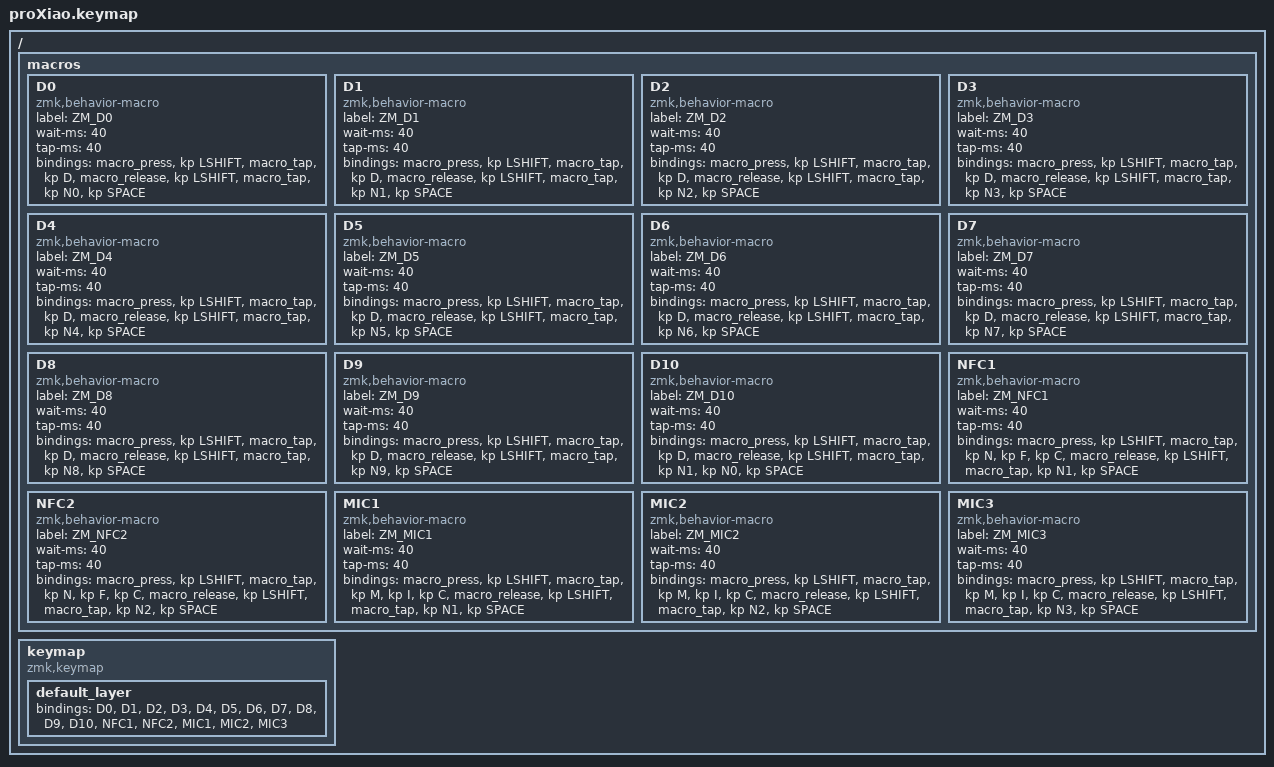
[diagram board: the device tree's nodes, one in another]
/*
 * Copyright (c) 2020 The ZMK Contributors
 *
 * SPDX-License-Identifier: MIT
 */

#include <behaviors.dtsi>
#include <dt-bindings/zmk/keys.h>
#include <dt-bindings/zmk/bt.h>

#include <dt-bindings/zmk/ext_power.h>


/ {
    macros {
        D0: D0 {
            label = "ZM_D0";
            compatible = "zmk,behavior-macro";
            #binding-cells = <0>;
            wait-ms = <40>;
            tap-ms = <40>;
            bindings
                = <&macro_press   &kp LSHIFT>    
                , <&macro_tap     &kp D>
                , <&macro_release &kp LSHIFT>
                , <&macro_tap     &kp N0  &kp SPACE> 
                ;
        };
        D1: D1 {
            label = "ZM_D1";
            compatible = "zmk,behavior-macro";
            #binding-cells = <0>;
            wait-ms = <40>;
            tap-ms = <40>;
            bindings
                = <&macro_press   &kp LSHIFT>    
                , <&macro_tap     &kp D> 
                , <&macro_release &kp LSHIFT>
                , <&macro_tap     &kp N1  &kp SPACE> 
                ;
        };
        D2: D2 {
            label = "ZM_D2";
            compatible = "zmk,behavior-macro";
            #binding-cells = <0>;
            wait-ms = <40>;
            tap-ms = <40>;
            bindings
                = <&macro_press   &kp LSHIFT>    
                , <&macro_tap     &kp D>   
                , <&macro_release &kp LSHIFT>
                , <&macro_tap     &kp N2  &kp SPACE> 
                ;
        };
        D3: D3 {
            label = "ZM_D3";
            compatible = "zmk,behavior-macro";
            #binding-cells = <0>;
            wait-ms = <40>;
            tap-ms = <40>;
            bindings
                = <&macro_press   &kp LSHIFT>    
                , <&macro_tap     &kp D>   
                , <&macro_release &kp LSHIFT>
                , <&macro_tap     &kp N3  &kp SPACE> 
                ;
        };
        D4: D4 {
            label = "ZM_D4";
            compatible = "zmk,behavior-macro";
            #binding-cells = <0>;
            wait-ms = <40>;
            tap-ms = <40>;
            bindings
                = <&macro_press   &kp LSHIFT>    
                , <&macro_tap     &kp D>   
                , <&macro_release &kp LSHIFT>
                , <&macro_tap     &kp N4  &kp SPACE> 
                ;
        };
        D5: D5 {
            label = "ZM_D5";
            compatible = "zmk,behavior-macro";
            #binding-cells = <0>;
            wait-ms = <40>;
            tap-ms = <40>;
            bindings
                = <&macro_press   &kp LSHIFT>    
                , <&macro_tap     &kp D>   
                , <&macro_release &kp LSHIFT>
                , <&macro_tap     &kp N5  &kp SPACE> 
                ;
        };
        D6: D6 {
            label = "ZM_D6";
            compatible = "zmk,behavior-macro";
            #binding-cells = <0>;
            wait-ms = <40>;
            tap-ms = <40>;
            bindings
                = <&macro_press   &kp LSHIFT>    
                , <&macro_tap     &kp D>   
                , <&macro_release &kp LSHIFT>
                , <&macro_tap     &kp N6  &kp SPACE> 
                ;
        };
        D7: D7 {
            label = "ZM_D7";
            compatible = "zmk,behavior-macro";
            #binding-cells = <0>;
            wait-ms = <40>;
            tap-ms = <40>;
            bindings
                = <&macro_press   &kp LSHIFT>    
                , <&macro_tap     &kp D>   
                , <&macro_release &kp LSHIFT>
                , <&macro_tap     &kp N7  &kp SPACE> 
                ;
        };
        D8: D8 {
            label = "ZM_D8";
            compatible = "zmk,behavior-macro";
            #binding-cells = <0>;
            wait-ms = <40>;
            tap-ms = <40>;
            bindings
                = <&macro_press   &kp LSHIFT>    
                , <&macro_tap     &kp D>   
                , <&macro_release &kp LSHIFT>
                , <&macro_tap     &kp N8  &kp SPACE>  
                ;
        };
        D9: D9 {
            label = "ZM_D9";
            compatible = "zmk,behavior-macro";
            #binding-cells = <0>;
            wait-ms = <40>;
            tap-ms = <40>;
            bindings
                = <&macro_press   &kp LSHIFT>    
                , <&macro_tap     &kp D>
                , <&macro_release &kp LSHIFT>
                , <&macro_tap     &kp N9  &kp SPACE> 
                ;
        };
        D10: D10 {
            label = "ZM_D10";
            compatible = "zmk,behavior-macro";
            #binding-cells = <0>;
            wait-ms = <40>;
            tap-ms = <40>;
            bindings
                = <&macro_press   &kp LSHIFT>    
                , <&macro_tap     &kp D>
                , <&macro_release &kp LSHIFT>
                , <&macro_tap     &kp N1 &kp N0 &kp SPACE> 
                ;
        };
        NFC1: NFC1 {
            label = "ZM_NFC1";
            compatible = "zmk,behavior-macro";
            #binding-cells = <0>;
            wait-ms = <40>;
            tap-ms = <40>;
            bindings
                = <&macro_press   &kp LSHIFT>    
                , <&macro_tap     &kp N &kp F &kp C>
                , <&macro_release &kp LSHIFT>
                , <&macro_tap     &kp N1  &kp SPACE> 
                ;
        };
        NFC2: NFC2 {
            label = "ZM_NFC2";
            compatible = "zmk,behavior-macro";
            #binding-cells = <0>;
            wait-ms = <40>;
            tap-ms = <40>;
            bindings
                = <&macro_press   &kp LSHIFT>    
                , <&macro_tap     &kp N &kp F &kp C>
                , <&macro_release &kp LSHIFT>
                , <&macro_tap     &kp N2  &kp SPACE> 
                ;
        };
        MIC1: MIC1 {
            label = "ZM_MIC1";
            compatible = "zmk,behavior-macro";
            #binding-cells = <0>;
            wait-ms = <40>;
            tap-ms = <40>;
            bindings
                = <&macro_press   &kp LSHIFT>    
                , <&macro_tap     &kp M &kp I &kp C>
                , <&macro_release &kp LSHIFT>
                , <&macro_tap     &kp N1  &kp SPACE> 
                ;
        };
        MIC2: MIC2 {
            label = "ZM_MIC2";
            compatible = "zmk,behavior-macro";
            #binding-cells = <0>;
            wait-ms = <40>;
            tap-ms = <40>;
            bindings
                = <&macro_press   &kp LSHIFT>    
                , <&macro_tap     &kp M &kp I &kp C>
                , <&macro_release &kp LSHIFT>
                , <&macro_tap     &kp N2  &kp SPACE> 
                ;
        };
        MIC3: MIC3 {
            label = "ZM_MIC3";
            compatible = "zmk,behavior-macro";
            #binding-cells = <0>;
            wait-ms = <40>;
            tap-ms = <40>;
            bindings
                = <&macro_press   &kp LSHIFT>    
                , <&macro_tap     &kp M &kp I &kp C>
                , <&macro_release &kp LSHIFT>
                , <&macro_tap     &kp N3  &kp SPACE> 
                ;
        };
    };
};


#define DEF 0

/ {
        keymap {
                compatible = "zmk,keymap";

                default_layer {
                        bindings = <
                        &D0 &D1 &D2 &D3 &D4 &D5 &D6 &D7 &D8 &D9 &D10 &NFC1 &NFC2 &MIC1 &MIC2 &MIC3
                        >;
                };
        };
};
/*
 * &kp A &kp B &kp C &kp D &kp E &kp F  &kp G &kp H &kp I &kp J &kp K &kp L &kp M 
*/
 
